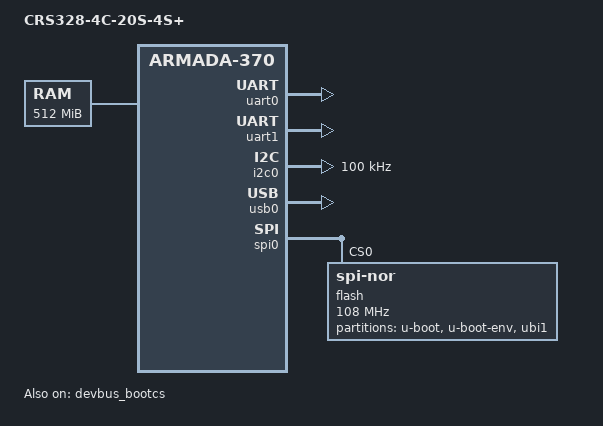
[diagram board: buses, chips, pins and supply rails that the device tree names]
/dts-v1/;
#include "armada-xp-98dx3236.dtsi"
/ {
	model = "CRS328-4C-20S-4S+";
	compatible = "mikrotik,crs328-4c-20s-4s", "marvell,armadaxp-98dx3236", "marvell,armada-370-xp";
	chosen {
		bootargs = "console=ttyS0,115200 earlyprintk";
	};
	memory {
		device_type = "memory";
		reg = <0 0x00000000 0 0x20000000>;  
	};
};
&L2 {
	arm,parity-enable;
	marvell,ecc-enable;
};
&devbus_bootcs {
	status = "okay";
	devbus,bus-width    = <16>;
	devbus,turn-off-ps  = <60000>;
	devbus,badr-skew-ps = <0>;
	devbus,acc-first-ps = <124000>;
	devbus,acc-next-ps  = <248000>;
	devbus,rd-setup-ps  = <0>;
	devbus,rd-hold-ps   = <0>;
	devbus,sync-enable = <0>;
	devbus,wr-high-ps  = <60000>;
	devbus,wr-low-ps   = <60000>;
	devbus,ale-wr-ps   = <60000>;
};
&uart0 {
	status = "okay";
};
&uart1 {
	status = "okay";
};
&i2c0 {
	clock-frequency = <100000>;
	status = "okay";
};
&usb0 {
	status = "okay";
};
&spi0 {
	status = "okay";
	flash@0 {
		#address-cells = <1>;
		#size-cells = <1>;
		compatible = "jedec,spi-nor";
		reg = <0>;  
		spi-max-frequency = <108000000>;
		m25p,fast-read;
		partition@u-boot {
			reg = <0x00000000 0x001f0000>;
			label = "u-boot";
		};
		partition@u-boot-env {
			reg = <0x001f0000 0x00010000>;
			label = "u-boot-env";
		};
		partition@ubi1 {
			reg = <0x00200000 0x00e00000>;
			label = "ubi1";
		};
	};
};
